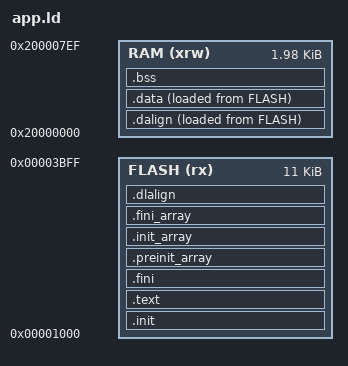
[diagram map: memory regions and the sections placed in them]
/* noknok CH32V003 module application linker
 *
 * The application runs UNDER the shared noknok I2C bootloader, which owns the
 * low 4 KB of flash. This script links the app at the 0x1000 offset so the
 * bootloader can `jr 0x1000` straight onto the app's InterruptVector
 * (= "j handle_reset").
 *
 * Flash map (16 KB total):
 *   0x0000_0000  bootloader   4 KB  (separate binary, SWD-flashed once)
 *   0x0000_1000  application  this image (linked here, flashed over I2C)
 *   0x0000_3C00  metadata     last 1 KB page  {magic, app_len, app_crc32}
 *
 * FLASH length is capped at 0x2C00 (11 KB) so the app can never reach the
 * metadata page at 0x3C00. The top 16 bytes of RAM are reserved for the no-init
 * handoff cell at 0x200007F0 (stack ends below it) — the same address the
 * bootloader reads, so a warm reset hands control over cleanly.
 */

ENTRY( InterruptVector )

MEMORY
{
	FLASH (rx) : ORIGIN = 0x00001000, LENGTH = 0x2C00   /* app: 11 KB, below metadata page */
	RAM (xrw)  : ORIGIN = 0x20000000, LENGTH = 2032     /* 2 KB - 16 B (handoff @ 0x200007F0) */
}

SECTIONS
{
	.init :
	{
		_sinit = .;
		. = ALIGN(4);
		KEEP(*(SORT_NONE(.init)))
		*(.text.vector_handler)
		. = ALIGN(4);
		_einit = .;
	} >FLASH AT>FLASH

	.text :
	{
		. = ALIGN(4);
		*(.text)
		*(.text.*)
		*(.rodata)
		*(.rodata*)
		*(.gnu.linkonce.t.*)
		. = ALIGN(4);
	} >FLASH AT>FLASH

	.fini :
	{
		KEEP(*(SORT_NONE(.fini)))
		. = ALIGN(4);
	} >FLASH AT>FLASH

	PROVIDE( _etext = . );

	.preinit_array :
	{
		PROVIDE_HIDDEN (__preinit_array_start = .);
		KEEP (*(.preinit_array))
		PROVIDE_HIDDEN (__preinit_array_end = .);
	} >FLASH AT>FLASH

	.init_array :
	{
		PROVIDE_HIDDEN (__init_array_start = .);
		KEEP (*(SORT_BY_INIT_PRIORITY(.init_array.*) SORT_BY_INIT_PRIORITY(.ctors.*)))
		KEEP (*(.init_array EXCLUDE_FILE (*crtbegin.o *crtbegin?.o *crtend.o *crtend?.o ) .ctors))
		PROVIDE_HIDDEN (__init_array_end = .);
	} >FLASH AT>FLASH

	.fini_array :
	{
		PROVIDE_HIDDEN (__fini_array_start = .);
		KEEP (*(SORT_BY_INIT_PRIORITY(.fini_array.*) SORT_BY_INIT_PRIORITY(.dtors.*)))
		KEEP (*(.fini_array EXCLUDE_FILE (*crtbegin.o *crtbegin?.o *crtend.o *crtend?.o ) .dtors))
		PROVIDE_HIDDEN (__fini_array_end = .);
	} >FLASH AT>FLASH

	.dalign :
	{
		. = ALIGN(4);
		PROVIDE(_data_vma = .);
	} >RAM AT>FLASH

	.dlalign :
	{
		. = ALIGN(4);
		PROVIDE(_data_lma = .);
	} >FLASH AT>FLASH

	.data :
	{
		. = ALIGN(4);
		*(.data.vector_handler)
		*(.gnu.linkonce.r.*)
		*(.data .data.*)
		*(.gnu.linkonce.d.*)
		. = ALIGN(8);
		PROVIDE( __global_pointer$ = . + 0x800 );
		*(.sdata .sdata.*)
		*(.sdata2*)
		*(.gnu.linkonce.s.*)
		. = ALIGN(8);
		*(.srodata.cst16)
		*(.srodata.cst8)
		*(.srodata.cst4)
		*(.srodata.cst2)
		*(.srodata .srodata.*)
		. = ALIGN(4);
		PROVIDE( _edata = .);
	} >RAM AT>FLASH

	.bss :
	{
		. = ALIGN(4);
		PROVIDE( _sbss = .);
		*(.sbss*)
		*(.gnu.linkonce.sb.*)
		*(.bss*)
		*(.gnu.linkonce.b.*)
		*(COMMON*)
		. = ALIGN(4);
		PROVIDE( _ebss = .);
	} >RAM

	PROVIDE( _end = _ebss);
	PROVIDE( end = . );

	PROVIDE( _eusrstack = ORIGIN(RAM) + LENGTH(RAM));   /* = 0x200007F0 */
}
